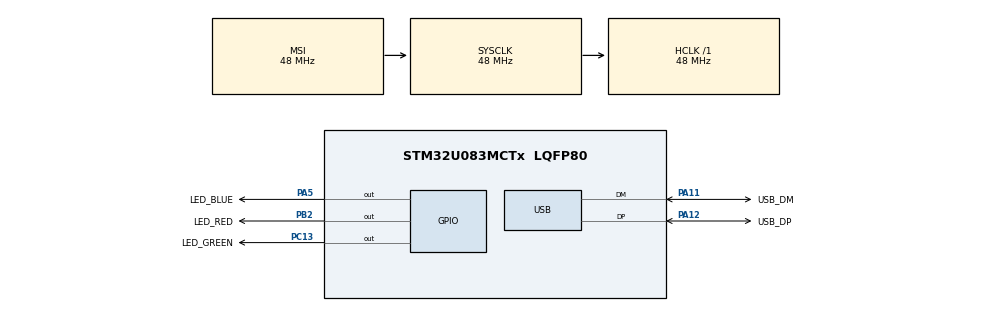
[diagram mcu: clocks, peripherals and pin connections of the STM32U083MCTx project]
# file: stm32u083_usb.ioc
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Mcu.Family=STM32U0
Mcu.Name=STM32U083MCTx
Mcu.Package=LQFP80
NVIC.PriorityGroup=NVIC_PRIORITYGROUP_2
NVIC.USB_DRD_FS_IRQn=true\:0\:0\:false\:false\:true\:true\:true\:true
PA11\ [PA9].GPIO_Label=USB_DM
PA11\ [PA9].Mode=Device
PA11\ [PA9].Signal=USB_DM
PA12\ [PA10].GPIO_Label=USB_DP
PA12\ [PA10].Mode=Device
PA12\ [PA10].Signal=USB_DP
PA13\ (SWDIO).GPIO_Label=SWDIO
PA13\ (SWDIO).Signal=DEBUG_JTMS-SWDIO
PA14\ (SWCLK).Signal=DEBUG_JTCK-SWCLK
PA5.GPIO_Label=LED_BLUE
PA5.Signal=GPIO_Output
PB2.GPIO_Label=LED_RED
PB2.Signal=GPIO_Output
PC13.GPIO_Label=LED_GREEN
PC13.Signal=GPIO_Output
ProjectManager.HeapSize=0x200
ProjectManager.StackSize=0x400
ProjectManager.TargetToolchain=STM32CubeIDE
RCC.ADCFreq_Value=48000000
RCC.AHBFreq_Value=48000000
RCC.CortexFreq_Value=48000000
RCC.HCLKFreq_Value=48000000
RCC.HSE_VALUE=4000000
RCC.HSI48_VALUE=48000000
RCC.HSI_VALUE=16000000
RCC.LSE_VALUE=32768
RCC.MSIClockRangeVal=RCC_MSIRANGE_11
RCC.MSI_VALUE=48000000
RCC.PLLN=6
RCC.SYSCLKFreq_VALUE=48000000
RCC.SYSCLKSource=RCC_SYSCLKSOURCE_MSI
RCC.USBCLockSelection=RCC_USBCLKSOURCE_HSI48
RCC.USBFreq_Value=48000000
RCC.VCOOutputFreq_Value=96000000
USB.VirtualMode=Device_Only
USBX.Core_System=1
USBX.USBD_CDCACM_EPIN_ADDR=2
USBX.USBD_CDCACM_EPOUT_ADDR=3
USBX.USBX_DEVICE_SYS_SIZE=3*1024
USBX.UX_DEBUG_LOG_SIZE=0
USBX.UX_DEVICE_APP_MEM_POOL_SIZE_STANDALONE=3*1024
USBX.UX_DEVICE_CDC_ACM=1
USBX.UX_Device_Controller=1
USBX.UX_Device_CoreStack=1
USBX.UX_MAX_DEVICE_ENDPOINTS=4
USBX.UX_MAX_DEVICE_INTERFACES=2
USBX.UX_MAX_SLAVE_INTERFACES=2
USBX.UX_SLAVE_REQUEST_CONTROL_MAX_LENGTH=256
USBX.UX_SLAVE_REQUEST_DATA_MAX_LENGTH=64
VP_PWR_VS_SECSignals.Mode=Security/Privilege
VP_RCC_USB.Mode=CRS SYNC Source USB
VP_USBX_Core_System.Mode=Core_System
VP_USBX_UX\ Device\ CDC\ ACM\ Class_FS.Mode=UX_Device_class_CDC_ACM_FS
VP_USBX_UX\ Device\ Controller_FS.Mode=UX_Device_Controller_FS
VP_USBX_UX\ Device\ CoreStack_FS.Mode=UX_Device_CoreStack_FS
board=STM32U083C-DK

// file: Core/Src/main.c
/* USER CODE BEGIN Header */
/**
  ******************************************************************************
  * @file           : main.c
  * @brief          : Main program body
  ******************************************************************************
  * @attention
  *
  * Copyright (c) 2026 STMicroelectronics.
  * All rights reserved.
  *
  * This software is licensed under terms that can be found in the LICENSE file
  * in the root directory of this software component.
  * If no LICENSE file comes with this software, it is provided AS-IS.
  *
  ******************************************************************************
  */
/* USER CODE END Header */
#include "main.h"
#include "app_usbx_device.h"

PCD_HandleTypeDef hpcd_USB_DRD_FS;

void SystemClock_Config(void);
static void MX_GPIO_Init(void);

int main(void)
{

  /* MCU Configuration--------------------------------------------------------*/

  /* Reset of all peripherals, Initializes the Flash interface and the Systick. */
  HAL_Init();

  /* Configure the system clock */
  SystemClock_Config();

  /* Initialize all configured peripherals */
  MX_GPIO_Init();
  /* USER CODE BEGIN 2 */
  /* Force USB onto real PA11/PA12, not the PA9/PA10 digital remap. */
  HAL_SYSCFG_DisableRemap(SYSCFG_REMAP_PA11 | SYSCFG_REMAP_PA12);

  if (MX_USBX_Device_Init() != UX_SUCCESS)
  {
    HAL_GPIO_WritePin(LED_RED_GPIO_Port, LED_RED_Pin, GPIO_PIN_SET);
    Error_Handler();
  }
  /* USER CODE END 2 */

  /* Infinite loop */
  while (1)
  {

    /* USER CODE BEGIN 3 */
	  USBX_Device_Process(NULL);
	  /* Heartbeat: firmware is alive. Frozen LED = hardfault after USB start. */
	  if ((HAL_GetTick() % 500U) < 50U)
	  {
	    HAL_GPIO_WritePin(LED_GREEN_GPIO_Port, LED_GREEN_Pin, GPIO_PIN_SET);
	  }
	  else
	  {
	    HAL_GPIO_WritePin(LED_GREEN_GPIO_Port, LED_GREEN_Pin, GPIO_PIN_RESET);
	  }
  }
  /* USER CODE END 3 */
}

void SystemClock_Config(void)
{
  RCC_OscInitTypeDef RCC_OscInitStruct = {0};
  RCC_ClkInitTypeDef RCC_ClkInitStruct = {0};
  RCC_CRSInitTypeDef RCC_CRSInitStruct = {0};

  /** Configure the main internal regulator output voltage
  */
  HAL_PWREx_ControlVoltageScaling(PWR_REGULATOR_VOLTAGE_SCALE1);

  /** Initializes the RCC Oscillators according to the specified parameters
  * in the RCC_OscInitTypeDef structure.
  */
  RCC_OscInitStruct.OscillatorType = RCC_OSCILLATORTYPE_HSI48|RCC_OSCILLATORTYPE_MSI;
  RCC_OscInitStruct.MSIState = RCC_MSI_ON;
  RCC_OscInitStruct.MSICalibrationValue = RCC_MSICALIBRATION_DEFAULT;
  RCC_OscInitStruct.MSIClockRange = RCC_MSIRANGE_11;
  RCC_OscInitStruct.HSI48State = RCC_HSI48_ON;
  RCC_OscInitStruct.PLL.PLLState = RCC_PLL_NONE;
  if (HAL_RCC_OscConfig(&RCC_OscInitStruct) != HAL_OK)
  {
    Error_Handler();
  }

  /** Initializes the CPU, AHB and APB buses clocks
  */
  RCC_ClkInitStruct.ClockType = RCC_CLOCKTYPE_HCLK|RCC_CLOCKTYPE_SYSCLK
                              |RCC_CLOCKTYPE_PCLK1;
  RCC_ClkInitStruct.SYSCLKSource = RCC_SYSCLKSOURCE_MSI;
  RCC_ClkInitStruct.AHBCLKDivider = RCC_SYSCLK_DIV1;
  RCC_ClkInitStruct.APB1CLKDivider = RCC_HCLK_DIV1;

  if (HAL_RCC_ClockConfig(&RCC_ClkInitStruct, FLASH_LATENCY_1) != HAL_OK)
  {
    Error_Handler();
  }

  /** Enable the CRS clock
  */
  __HAL_RCC_CRS_CLK_ENABLE();

  /** Configures CRS
  */
  RCC_CRSInitStruct.Prescaler = RCC_CRS_SYNC_DIV1;
  RCC_CRSInitStruct.Source = RCC_CRS_SYNC_SOURCE_USB;
  RCC_CRSInitStruct.Polarity = RCC_CRS_SYNC_POLARITY_RISING;
  RCC_CRSInitStruct.ReloadValue = __HAL_RCC_CRS_RELOADVALUE_CALCULATE(48000000,1000);
  RCC_CRSInitStruct.ErrorLimitValue = 34;
  RCC_CRSInitStruct.HSI48CalibrationValue = 32;

  HAL_RCCEx_CRSConfig(&RCC_CRSInitStruct);
}

void MX_USB_PCD_Init(void)
{

  hpcd_USB_DRD_FS.Instance = USB_DRD_FS;
  hpcd_USB_DRD_FS.Init.dev_endpoints = 8;
  hpcd_USB_DRD_FS.Init.speed = USBD_FS_SPEED;
  hpcd_USB_DRD_FS.Init.phy_itface = PCD_PHY_EMBEDDED;
  hpcd_USB_DRD_FS.Init.Sof_enable = DISABLE;
  hpcd_USB_DRD_FS.Init.low_power_enable = DISABLE;
  hpcd_USB_DRD_FS.Init.lpm_enable = DISABLE;
  hpcd_USB_DRD_FS.Init.battery_charging_enable = DISABLE;
  if (HAL_PCD_Init(&hpcd_USB_DRD_FS) != HAL_OK)
  {
    Error_Handler();
  }
  /* USER CODE BEGIN USB_Init 2 */
  /* Official STM32CubeU0 U083 CDC map. Must match ux_device_descriptors.h. */
  HAL_PCDEx_PMAConfig(&hpcd_USB_DRD_FS, 0x00, PCD_SNG_BUF, 0x14);
  HAL_PCDEx_PMAConfig(&hpcd_USB_DRD_FS, 0x80, PCD_SNG_BUF, 0x54);
  HAL_PCDEx_PMAConfig(&hpcd_USB_DRD_FS, 0x81, PCD_SNG_BUF, 0x94);
  HAL_PCDEx_PMAConfig(&hpcd_USB_DRD_FS, 0x01, PCD_SNG_BUF, 0xD4);
  HAL_PCDEx_PMAConfig(&hpcd_USB_DRD_FS, 0x82, PCD_SNG_BUF, 0x114);
  /* USER CODE END USB_Init 2 */

}

static void MX_GPIO_Init(void)
{
  GPIO_InitTypeDef GPIO_InitStruct = {0};

  /* GPIO Ports Clock Enable */
  __HAL_RCC_GPIOC_CLK_ENABLE();
  __HAL_RCC_GPIOA_CLK_ENABLE();
  __HAL_RCC_GPIOB_CLK_ENABLE();

  /*Configure GPIO pin Output Level */
  HAL_GPIO_WritePin(LED_GREEN_GPIO_Port, LED_GREEN_Pin, GPIO_PIN_RESET);

  /*Configure GPIO pin Output Level */
  HAL_GPIO_WritePin(LED_BLUE_GPIO_Port, LED_BLUE_Pin, GPIO_PIN_RESET);

  /*Configure GPIO pin Output Level */
  HAL_GPIO_WritePin(LED_RED_GPIO_Port, LED_RED_Pin, GPIO_PIN_RESET);

  /*Configure GPIO pin : LED_GREEN_Pin */
  GPIO_InitStruct.Pin = LED_GREEN_Pin;
  GPIO_InitStruct.Mode = GPIO_MODE_OUTPUT_PP;
  GPIO_InitStruct.Pull = GPIO_NOPULL;
  GPIO_InitStruct.Speed = GPIO_SPEED_FREQ_LOW;
  HAL_GPIO_Init(LED_GREEN_GPIO_Port, &GPIO_InitStruct);

  /*Configure GPIO pin : LED_BLUE_Pin */
  GPIO_InitStruct.Pin = LED_BLUE_Pin;
  GPIO_InitStruct.Mode = GPIO_MODE_OUTPUT_PP;
  GPIO_InitStruct.Pull = GPIO_NOPULL;
  GPIO_InitStruct.Speed = GPIO_SPEED_FREQ_LOW;
  HAL_GPIO_Init(LED_BLUE_GPIO_Port, &GPIO_InitStruct);

  /*Configure GPIO pin : LED_RED_Pin */
  GPIO_InitStruct.Pin = LED_RED_Pin;
  GPIO_InitStruct.Mode = GPIO_MODE_OUTPUT_PP;
  GPIO_InitStruct.Pull = GPIO_NOPULL;
  GPIO_InitStruct.Speed = GPIO_SPEED_FREQ_LOW;
  HAL_GPIO_Init(LED_RED_GPIO_Port, &GPIO_InitStruct);

}

void Error_Handler(void)
{
  __disable_irq();
  while (1)
  {
  }
}
